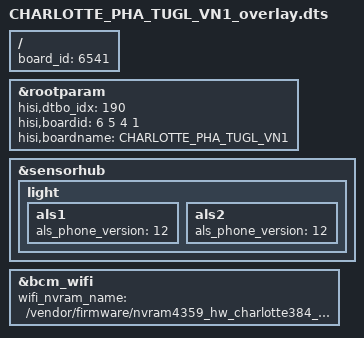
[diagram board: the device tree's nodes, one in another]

/**
 * Copyright (C) 2014 Hisilicon Ltd.
 *
 *  This program is free software; you can redistribute it and/or modify
 *  it under the terms of the GNU General Public License version 2 as
 *  publishhed by the Free Software Foundation.
 */

/dts-v1/;
/plugin/;
/include/ "CHARLOTTE_TUGL_V4_overlay.dtsi"

/ {
        board_id = <6541>;
};

&rootparam {
        hisi,dtbo_idx = <190>;
    hisi,boardid = <6 5 4 1>;
    hisi,boardname = "CHARLOTTE_PHA_TUGL_VN1";
};


&sensorhub {
	light{
		als1{
			als_phone_version = <12>;
		};
		als2{
			als_phone_version = <12>;
		};
	};
};

&bcm_wifi {
	wifi_nvram_name = "/vendor/firmware/nvram4359_hw_charlotte384_v1_phase.txt";
};
